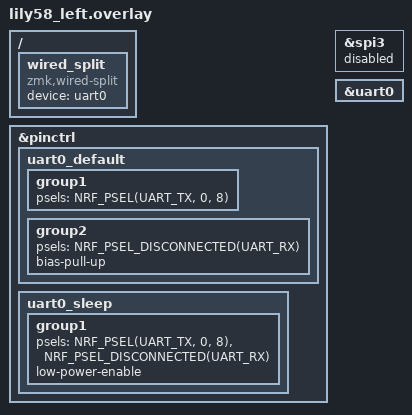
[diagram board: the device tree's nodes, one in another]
/*
 * Wired split over TRRS cable, single data wire.
 * Left = peripheral = TX only.
 * uart0 TX reassigned to P0.08 (D0) — the one TRRS data pin.
 * uart0 RX disconnected (not needed for peripheral→central key events).
 */

#include <zephyr/dt-bindings/pinctrl/nrf-pinctrl.h>

&pinctrl {
    uart0_default: uart0_default {
        group1 {
            psels = <NRF_PSEL(UART_TX, 0, 8)>;
        };
        group2 {
            psels = <NRF_PSEL_DISCONNECTED(UART_RX)>;
            bias-pull-up;
        };
    };
    uart0_sleep: uart0_sleep {
        group1 {
            psels = <NRF_PSEL(UART_TX, 0, 8)>,
                    <NRF_PSEL_DISCONNECTED(UART_RX)>;
            low-power-enable;
        };
    };
};

&spi3 {
    status = "disabled";
};

&uart0 {
    status = "okay";
};

/ {
    wired_split: wired_split {
        compatible = "zmk,wired-split";
        device = <&uart0>;
    };
};
